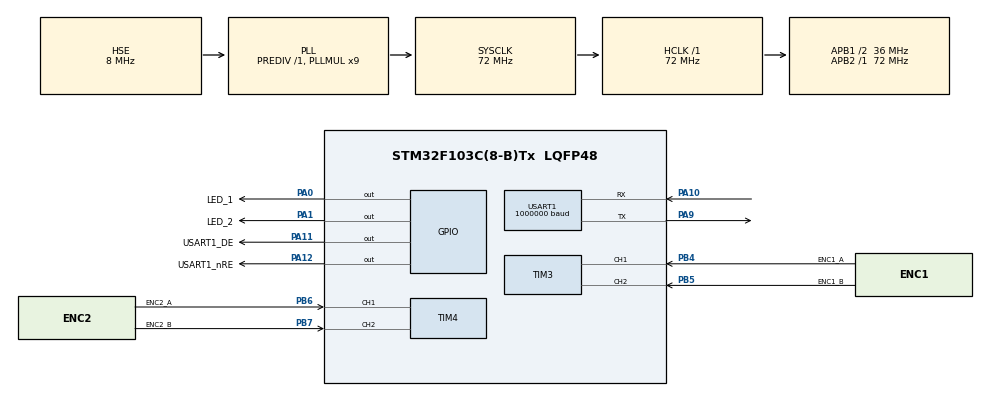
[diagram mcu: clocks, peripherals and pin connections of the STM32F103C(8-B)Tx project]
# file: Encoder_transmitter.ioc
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Dma.Request0=USART1_RX
Dma.Request1=USART1_TX
Dma.USART1_RX.0.Direction=DMA_PERIPH_TO_MEMORY
Dma.USART1_RX.0.Instance=DMA1_Channel5
Dma.USART1_RX.0.MemDataAlignment=DMA_MDATAALIGN_BYTE
Dma.USART1_RX.0.MemInc=DMA_MINC_ENABLE
Dma.USART1_RX.0.Mode=DMA_CIRCULAR
Dma.USART1_RX.0.PeriphDataAlignment=DMA_PDATAALIGN_BYTE
Dma.USART1_RX.0.PeriphInc=DMA_PINC_DISABLE
Dma.USART1_RX.0.Priority=DMA_PRIORITY_LOW
Dma.USART1_TX.1.Direction=DMA_MEMORY_TO_PERIPH
Dma.USART1_TX.1.Instance=DMA1_Channel4
Dma.USART1_TX.1.MemDataAlignment=DMA_MDATAALIGN_BYTE
Dma.USART1_TX.1.MemInc=DMA_MINC_ENABLE
Dma.USART1_TX.1.Mode=DMA_NORMAL
Dma.USART1_TX.1.PeriphDataAlignment=DMA_PDATAALIGN_BYTE
Dma.USART1_TX.1.PeriphInc=DMA_PINC_DISABLE
Dma.USART1_TX.1.Priority=DMA_PRIORITY_LOW
Mcu.Family=STM32F1
Mcu.Name=STM32F103C(8-B)Tx
Mcu.Package=LQFP48
NVIC.DMA1_Channel4_IRQn=true\:0\:0\:false\:false\:true\:false\:true\:true
NVIC.DMA1_Channel5_IRQn=true\:0\:0\:false\:false\:true\:false\:true\:true
NVIC.PriorityGroup=NVIC_PRIORITYGROUP_4
NVIC.USART1_IRQn=true\:0\:0\:false\:false\:true\:false\:true\:true
PA0-WKUP.GPIO_Label=LED_1
PA0-WKUP.Signal=GPIO_Output
PA1.GPIO_Label=LED_2
PA1.Signal=GPIO_Output
PA10.Mode=Asynchronous
PA10.Signal=USART1_RX
PA11.GPIO_Label=USART1_DE
PA11.PinState=GPIO_PIN_SET
PA11.Signal=GPIO_Output
PA12.GPIO_Label=USART1_nRE
PA12.PinState=GPIO_PIN_RESET
PA12.Signal=GPIO_Output
PA13.Mode=Trace_Asynchronous_SW
PA13.Signal=SYS_JTMS-SWDIO
PA14.Mode=Trace_Asynchronous_SW
PA14.Signal=SYS_JTCK-SWCLK
PA9.Mode=Asynchronous
PA9.Signal=USART1_TX
PB3.Mode=Trace_Asynchronous_SW
PB3.Signal=SYS_JTDO-TRACESWO
PB4.GPIO_Label=ENC1_A
PB4.Signal=S_TIM3_CH1
PB5.GPIO_Label=ENC1_B
PB5.Signal=S_TIM3_CH2
PB6.GPIO_Label=ENC2_A
PB6.Signal=S_TIM4_CH1
PB7.GPIO_Label=ENC2_B
PB7.Signal=S_TIM4_CH2
PD0-OSC_IN.Mode=HSE-External-Oscillator
PD0-OSC_IN.Signal=RCC_OSC_IN
PD1-OSC_OUT.Mode=HSE-External-Oscillator
PD1-OSC_OUT.Signal=RCC_OSC_OUT
ProjectManager.HeapSize=0x200
ProjectManager.StackSize=0x400
ProjectManager.TargetToolchain=STM32CubeIDE
RCC.AHBFreq_Value=72000000
RCC.APB1CLKDivider=RCC_HCLK_DIV2
RCC.APB1Freq_Value=36000000
RCC.APB1TimFreq_Value=72000000
RCC.APB2Freq_Value=72000000
RCC.APB2TimFreq_Value=72000000
RCC.HCLKFreq_Value=72000000
RCC.PLLMUL=RCC_PLL_MUL9
RCC.PLLSourceVirtual=RCC_PLLSOURCE_HSE
RCC.SYSCLKFreq_VALUE=72000000
RCC.SYSCLKSource=RCC_SYSCLKSOURCE_PLLCLK
RCC.USBFreq_Value=72000000
SH.S_TIM3_CH1.0=TIM3_CH1,Encoder_Interface
SH.S_TIM3_CH2.0=TIM3_CH2,Encoder_Interface
SH.S_TIM4_CH1.0=TIM4_CH1,Encoder_Interface
SH.S_TIM4_CH2.0=TIM4_CH2,Encoder_Interface
TIM3.EncoderMode=TIM_ENCODERMODE_TI12
USART1.BaudRate=1000000
USART1.VirtualMode=VM_ASYNC
board=custom

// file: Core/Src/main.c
/* USER CODE BEGIN Header */
/**
  ******************************************************************************
  * @file           : main.c
  * @brief          : Main program body
  ******************************************************************************
  * @attention
  *
  * Copyright (c) 2026 STMicroelectronics.
  * All rights reserved.
  *
  * This software is licensed under terms that can be found in the LICENSE file
  * in the root directory of this software component.
  * If no LICENSE file comes with this software, it is provided AS-IS.
  *
  ******************************************************************************
  */
/* USER CODE END Header */
#include "main.h"

/* USER CODE BEGIN Includes */
#include "incremental_enc.h"
#include "comm_dummy_rls.h"
/* USER CODE END Includes */

TIM_HandleTypeDef htim3;
TIM_HandleTypeDef htim4;

UART_HandleTypeDef huart1;
DMA_HandleTypeDef hdma_usart1_rx;
DMA_HandleTypeDef hdma_usart1_tx;

/* USER CODE BEGIN PV */
extern LinearEncoder_t ENC[2];
/* USER CODE END PV */

void SystemClock_Config(void);
static void MX_GPIO_Init(void);
static void MX_DMA_Init(void);
static void MX_USART1_UART_Init(void);
static void MX_TIM3_Init(void);
static void MX_TIM4_Init(void);

int main(void)
{

  /* MCU Configuration--------------------------------------------------------*/

  /* Reset of all peripherals, Initializes the Flash interface and the Systick. */
  HAL_Init();

  /* Configure the system clock */
  SystemClock_Config();

  /* Initialize all configured peripherals */
  MX_GPIO_Init();
  MX_DMA_Init();
  MX_USART1_UART_Init();
  MX_TIM3_Init();
  MX_TIM4_Init();
  /* USER CODE BEGIN 2 */
  ENC_INIT();
  UART_RLS_INIT();
  HAL_GPIO_WritePin(USART1_nRE_GPIO_Port, USART1_nRE_Pin, GPIO_PIN_RESET);
  HAL_GPIO_WritePin(USART1_DE_GPIO_Port, USART1_DE_Pin, GPIO_PIN_SET);
  /* USER CODE END 2 */

  /* Infinite loop */
  /* USER CODE BEGIN WHILE */
  while (1)
  {
	ENC_UPDATE(&ENC[0], &htim3);
	ENC_UPDATE(&ENC[1], &htim4);

	HAL_GPIO_WritePin(LED_1_GPIO_Port, LED_1_Pin, (ENC[0].delta_cnt != 0) ? GPIO_PIN_SET : GPIO_PIN_RESET);
	HAL_GPIO_WritePin(LED_2_GPIO_Port, LED_2_Pin, (ENC[1].delta_cnt != 0) ? GPIO_PIN_SET : GPIO_PIN_RESET);

	Delay_Cycles(72); //delay 1us
    /* USER CODE END WHILE */

  }
}

void SystemClock_Config(void)
{
  RCC_OscInitTypeDef RCC_OscInitStruct = {0};
  RCC_ClkInitTypeDef RCC_ClkInitStruct = {0};

  /** Initializes the RCC Oscillators according to the specified parameters
  * in the RCC_OscInitTypeDef structure.
  */
  RCC_OscInitStruct.OscillatorType = RCC_OSCILLATORTYPE_HSE;
  RCC_OscInitStruct.HSEState = RCC_HSE_ON;
  RCC_OscInitStruct.HSEPredivValue = RCC_HSE_PREDIV_DIV1;
  RCC_OscInitStruct.HSIState = RCC_HSI_ON;
  RCC_OscInitStruct.PLL.PLLState = RCC_PLL_ON;
  RCC_OscInitStruct.PLL.PLLSource = RCC_PLLSOURCE_HSE;
  RCC_OscInitStruct.PLL.PLLMUL = RCC_PLL_MUL9;
  if (HAL_RCC_OscConfig(&RCC_OscInitStruct) != HAL_OK)
  {
    Error_Handler();
  }

  /** Initializes the CPU, AHB and APB buses clocks
  */
  RCC_ClkInitStruct.ClockType = RCC_CLOCKTYPE_HCLK|RCC_CLOCKTYPE_SYSCLK
                              |RCC_CLOCKTYPE_PCLK1|RCC_CLOCKTYPE_PCLK2;
  RCC_ClkInitStruct.SYSCLKSource = RCC_SYSCLKSOURCE_PLLCLK;
  RCC_ClkInitStruct.AHBCLKDivider = RCC_SYSCLK_DIV1;
  RCC_ClkInitStruct.APB1CLKDivider = RCC_HCLK_DIV2;
  RCC_ClkInitStruct.APB2CLKDivider = RCC_HCLK_DIV1;

  if (HAL_RCC_ClockConfig(&RCC_ClkInitStruct, FLASH_LATENCY_2) != HAL_OK)
  {
    Error_Handler();
  }
}

static void MX_TIM3_Init(void)
{

  TIM_Encoder_InitTypeDef sConfig = {0};
  TIM_MasterConfigTypeDef sMasterConfig = {0};

  htim3.Instance = TIM3;
  htim3.Init.Prescaler = 0;
  htim3.Init.CounterMode = TIM_COUNTERMODE_UP;
  htim3.Init.Period = 65535;
  htim3.Init.ClockDivision = TIM_CLOCKDIVISION_DIV1;
  htim3.Init.AutoReloadPreload = TIM_AUTORELOAD_PRELOAD_DISABLE;
  sConfig.EncoderMode = TIM_ENCODERMODE_TI12;
  sConfig.IC1Polarity = TIM_ICPOLARITY_RISING;
  sConfig.IC1Selection = TIM_ICSELECTION_DIRECTTI;
  sConfig.IC1Prescaler = TIM_ICPSC_DIV1;
  sConfig.IC1Filter = 0;
  sConfig.IC2Polarity = TIM_ICPOLARITY_RISING;
  sConfig.IC2Selection = TIM_ICSELECTION_DIRECTTI;
  sConfig.IC2Prescaler = TIM_ICPSC_DIV1;
  sConfig.IC2Filter = 0;
  if (HAL_TIM_Encoder_Init(&htim3, &sConfig) != HAL_OK)
  {
    Error_Handler();
  }
  sMasterConfig.MasterOutputTrigger = TIM_TRGO_RESET;
  sMasterConfig.MasterSlaveMode = TIM_MASTERSLAVEMODE_DISABLE;
  if (HAL_TIMEx_MasterConfigSynchronization(&htim3, &sMasterConfig) != HAL_OK)
  {
    Error_Handler();
  }

}

static void MX_TIM4_Init(void)
{

  TIM_Encoder_InitTypeDef sConfig = {0};
  TIM_MasterConfigTypeDef sMasterConfig = {0};

  htim4.Instance = TIM4;
  htim4.Init.Prescaler = 0;
  htim4.Init.CounterMode = TIM_COUNTERMODE_UP;
  htim4.Init.Period = 65535;
  htim4.Init.ClockDivision = TIM_CLOCKDIVISION_DIV1;
  htim4.Init.AutoReloadPreload = TIM_AUTORELOAD_PRELOAD_DISABLE;
  sConfig.EncoderMode = TIM_ENCODERMODE_TI1;
  sConfig.IC1Polarity = TIM_ICPOLARITY_RISING;
  sConfig.IC1Selection = TIM_ICSELECTION_DIRECTTI;
  sConfig.IC1Prescaler = TIM_ICPSC_DIV1;
  sConfig.IC1Filter = 0;
  sConfig.IC2Polarity = TIM_ICPOLARITY_RISING;
  sConfig.IC2Selection = TIM_ICSELECTION_DIRECTTI;
  sConfig.IC2Prescaler = TIM_ICPSC_DIV1;
  sConfig.IC2Filter = 0;
  if (HAL_TIM_Encoder_Init(&htim4, &sConfig) != HAL_OK)
  {
    Error_Handler();
  }
  sMasterConfig.MasterOutputTrigger = TIM_TRGO_RESET;
  sMasterConfig.MasterSlaveMode = TIM_MASTERSLAVEMODE_DISABLE;
  if (HAL_TIMEx_MasterConfigSynchronization(&htim4, &sMasterConfig) != HAL_OK)
  {
    Error_Handler();
  }

}

static void MX_USART1_UART_Init(void)
{

  huart1.Instance = USART1;
  huart1.Init.BaudRate = 1000000;
  huart1.Init.WordLength = UART_WORDLENGTH_8B;
  huart1.Init.StopBits = UART_STOPBITS_1;
  huart1.Init.Parity = UART_PARITY_NONE;
  huart1.Init.Mode = UART_MODE_TX_RX;
  huart1.Init.HwFlowCtl = UART_HWCONTROL_NONE;
  huart1.Init.OverSampling = UART_OVERSAMPLING_16;
  if (HAL_UART_Init(&huart1) != HAL_OK)
  {
    Error_Handler();
  }

}

static void MX_DMA_Init(void)
{

  /* DMA controller clock enable */
  __HAL_RCC_DMA1_CLK_ENABLE();

  /* DMA interrupt init */
  /* DMA1_Channel4_IRQn interrupt configuration */
  HAL_NVIC_SetPriority(DMA1_Channel4_IRQn, 0, 0);
  HAL_NVIC_EnableIRQ(DMA1_Channel4_IRQn);
  /* DMA1_Channel5_IRQn interrupt configuration */
  HAL_NVIC_SetPriority(DMA1_Channel5_IRQn, 0, 0);
  HAL_NVIC_EnableIRQ(DMA1_Channel5_IRQn);

}

static void MX_GPIO_Init(void)
{
  GPIO_InitTypeDef GPIO_InitStruct = {0};

  /* GPIO Ports Clock Enable */
  __HAL_RCC_GPIOD_CLK_ENABLE();
  __HAL_RCC_GPIOA_CLK_ENABLE();
  __HAL_RCC_GPIOB_CLK_ENABLE();

  /*Configure GPIO pin Output Level */
  HAL_GPIO_WritePin(GPIOA, LED_1_Pin|LED_2_Pin|USART1_nRE_Pin, GPIO_PIN_RESET);

  /*Configure GPIO pin Output Level */
  HAL_GPIO_WritePin(USART1_DE_GPIO_Port, USART1_DE_Pin, GPIO_PIN_SET);

  /*Configure GPIO pins : LED_1_Pin LED_2_Pin USART1_DE_Pin USART1_nRE_Pin */
  GPIO_InitStruct.Pin = LED_1_Pin|LED_2_Pin|USART1_DE_Pin|USART1_nRE_Pin;
  GPIO_InitStruct.Mode = GPIO_MODE_OUTPUT_PP;
  GPIO_InitStruct.Pull = GPIO_NOPULL;
  GPIO_InitStruct.Speed = GPIO_SPEED_FREQ_LOW;
  HAL_GPIO_Init(GPIOA, &GPIO_InitStruct);

}

void Error_Handler(void)
{
  __disable_irq();
  while (1)
  {
  }
}
